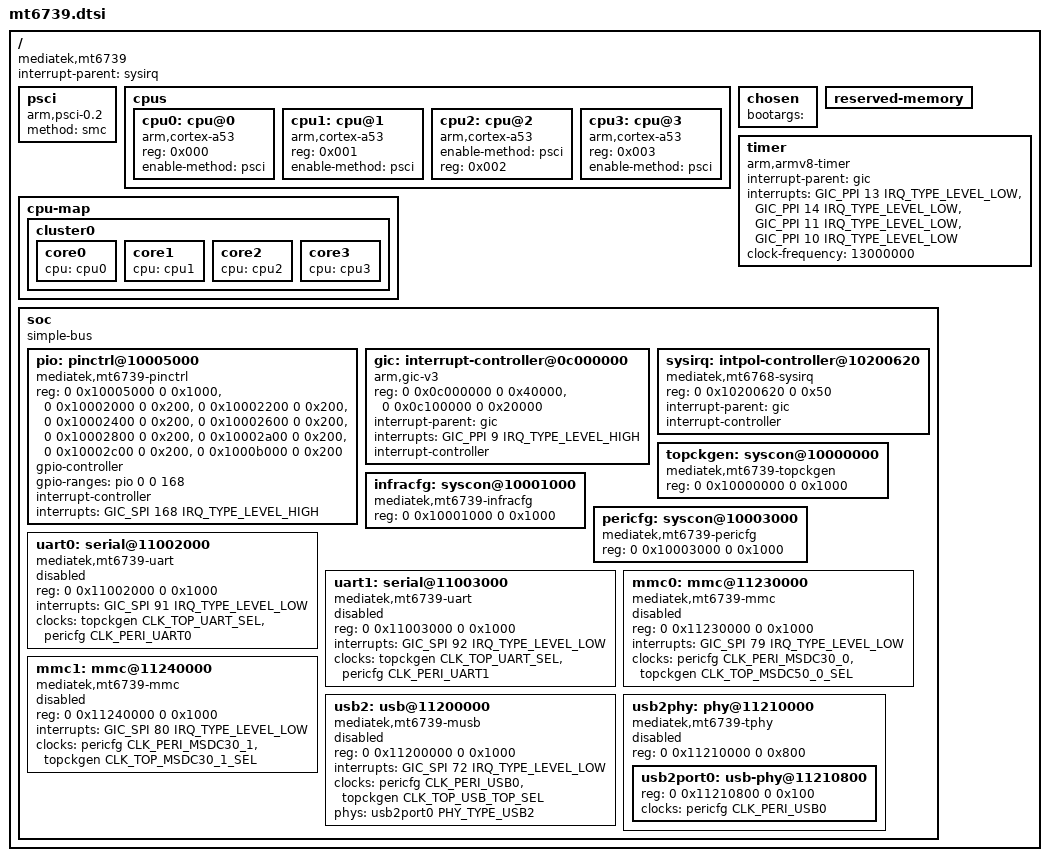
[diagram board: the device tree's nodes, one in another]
// SPDX-License-Identifier: GPL-2.0
/*
 * Copyright (c) 2024 Hoang Long
 */

#include <dt-bindings/clock/mt6739-clk.h>
#include <dt-bindings/interrupt-controller/irq.h>
#include <dt-bindings/interrupt-controller/arm-gic.h>
#include <dt-bindings/phy/phy.h>
#include <dt-bindings/pinctrl/mediatek,mt6739-pinfunc.h>

/ {
    compatible = "mediatek,mt6739";
    interrupt-parent = <&sysirq>;
    #address-cells = <2>;
    #size-cells = <2>;

    psci {
        compatible = "arm,psci-0.2";
        method = "smc";
    };

    cpus {
        #address-cells = <1>;
        #size-cells = <0>;

        cpu0: cpu@0 {
            device_type = "cpu";
            compatible = "arm,cortex-a53";
            reg = <0x000>;
            enable-method = "psci";
        };

        cpu1: cpu@1 {
            device_type = "cpu";
            compatible = "arm,cortex-a53";
            reg = <0x001>;
            enable-method = "psci";
        };

        cpu2: cpu@2 {
            device_type = "cpu";
            compatible = "arm,cortex-a53";
            enable-method = "psci";
            reg = <0x002>;
        };

        cpu3: cpu@3 {
            device_type = "cpu";
            compatible = "arm,cortex-a53";
            reg = <0x003>;
            enable-method = "psci";
        };
    };

    cpu-map {
        cluster0 {
            core0 {
                cpu = <&cpu0>;
            };
            core1 {
                cpu = <&cpu1>;
            };
            core2 {
                cpu = <&cpu2>;
            };
            core3 {
                cpu = <&cpu3>;
            };
        };
    };

	chosen {
		#address-cells = <2>;
		#size-cells = <2>;
		ranges;

		/*
		 * NOTE: /chosen/bootargs has to exist even if unused or
		 * bootloader will be unhappy
		 */
		bootargs = "";
	};

	reserved-memory {
		#address-cells = <2>;
		#size-cells = <2>;
		ranges;

		/* TODO: add useful non-mblock nodes from downstream! */
	};

    timer {
        compatible = "arm,armv8-timer";
        interrupt-parent = <&gic>;
        interrupts = <GIC_PPI 13 IRQ_TYPE_LEVEL_LOW>,
                     <GIC_PPI 14 IRQ_TYPE_LEVEL_LOW>,
                     <GIC_PPI 11 IRQ_TYPE_LEVEL_LOW>,
                     <GIC_PPI 10 IRQ_TYPE_LEVEL_LOW>;
        clock-frequency = <13000000>;
    };

    soc {
        #address-cells = <2>;
        #size-cells = <2>;
        compatible = "simple-bus";
        ranges;

        pio: pinctrl@10005000 {
            compatible = "mediatek,mt6739-pinctrl";
            reg = <0 0x10005000 0 0x1000>,
                  <0 0x10002000 0 0x200>,
                  <0 0x10002200 0 0x200>,
                  <0 0x10002400 0 0x200>,
                  <0 0x10002600 0 0x200>,
                  <0 0x10002800 0 0x200>,
                  <0 0x10002a00 0 0x200>,
                  <0 0x10002c00 0 0x200>,
                  <0 0x1000b000 0 0x200>;
            reg-names = "gpio", "iocfg_lt", "iocfg_lm", "iocfg_lb",
                  "iocfg_bl", "iocfg_bm", "iocfg_rb", "iocfg_rt",
                  "eint";
            gpio-controller;
            #gpio-cells = <2>;
            gpio-ranges = <&pio 0 0 168>;
            interrupt-controller;
            interrupts = <GIC_SPI 168 IRQ_TYPE_LEVEL_HIGH>;
            #interrupt-cells = <2>;
        };

        gic: interrupt-controller@0c000000 {
            compatible = "arm,gic-v3";
            reg = <0 0x0c000000 0 0x40000>, /* GICD */
                  <0 0x0c100000 0 0x20000>; /* GICR */
            #interrupt-cells = <3>;
            interrupt-parent = <&gic>;
            interrupts = <GIC_PPI 9 IRQ_TYPE_LEVEL_HIGH>;
            interrupt-controller;
        };

        sysirq: intpol-controller@10200620 {
			compatible = "mediatek,mt6768-sysirq", "mediatek,mt6577-sysirq";
            reg = <0 0x10200620 0 0x50>;	/* INTPOL */
            #interrupt-cells = <3>;
            interrupt-parent = <&gic>;
            interrupt-controller;
        };

        topckgen: syscon@10000000 {
            compatible = "mediatek,mt6739-topckgen", "syscon";
            reg = <0 0x10000000 0 0x1000>;
            #clock-cells = <1>;
        };

        infracfg: syscon@10001000 {
            compatible = "mediatek,mt6739-infracfg", "syscon";
            reg = <0 0x10001000 0 0x1000>;
            #clock-cells = <1>;
        };

        pericfg: syscon@10003000 {
            compatible = "mediatek,mt6739-pericfg", "syscon";
            reg = <0 0x10003000 0 0x1000>;
            #clock-cells = <1>;
        };

        uart0: serial@11002000 {
            compatible = "mediatek,mt6739-uart", "mediatek,mt6577-uart";
            reg = <0 0x11002000 0 0x1000>;
            interrupts = <GIC_SPI 91 IRQ_TYPE_LEVEL_LOW>;
            clocks = <&topckgen CLK_TOP_UART_SEL>, <&pericfg CLK_PERI_UART0>;
            clock-names = "baud", "bus";
            status = "disabled";
        };

        uart1: serial@11003000 {
            compatible = "mediatek,mt6739-uart", "mediatek,mt6577-uart";
            reg = <0 0x11003000 0 0x1000>;
            interrupts = <GIC_SPI 92 IRQ_TYPE_LEVEL_LOW>;
            clocks = <&topckgen CLK_TOP_UART_SEL>, <&pericfg CLK_PERI_UART1>;
            clock-names = "baud", "bus";
            status = "disabled";
        };

        mmc0: mmc@11230000 {
            compatible = "mediatek,mt6739-mmc", "mediatek,mt6765-mmc";
            reg = <0 0x11230000 0 0x1000>;
            interrupts = <GIC_SPI 79 IRQ_TYPE_LEVEL_LOW>;
            clocks = <&pericfg CLK_PERI_MSDC30_0>,
                     <&topckgen CLK_TOP_MSDC50_0_SEL>;
            clock-names = "source", "hclk";
            status = "disabled";
        };

        mmc1: mmc@11240000 {
            compatible = "mediatek,mt6739-mmc", "mediatek,mt6765-mmc";
            reg = <0 0x11240000 0 0x1000>;
            interrupts = <GIC_SPI 80 IRQ_TYPE_LEVEL_LOW>;
            clocks = <&pericfg CLK_PERI_MSDC30_1>,
                     <&topckgen CLK_TOP_MSDC30_1_SEL>;
            clock-names = "source", "hclk";
            status = "disabled";
        };

        usb2: usb@11200000 {
            compatible = "mediatek,mt6739-musb", "mediatek,mtk-musb";
            reg = <0 0x11200000 0 0x1000>;
            interrupts = <GIC_SPI 72 IRQ_TYPE_LEVEL_LOW>;
            interrupt-names = "mc";
            clocks = <&pericfg CLK_PERI_USB0>,
                     <&topckgen CLK_TOP_USB_TOP_SEL>;
            clock-names = "main", "mcu";
            phys = <&usb2port0 PHY_TYPE_USB2>;
            status = "disabled";
        };

        usb2phy: phy@11210000 {
            compatible = "mediatek,mt6739-tphy", "mediatek,generic-tphy-v1";
            reg = <0 0x11210000 0 0x800>;
            #address-cells = <2>;
            #size-cells = <2>;
            ranges;
            status = "disabled";

            usb2port0: usb-phy@11210800 {
                reg = <0 0x11210800 0 0x100>;
                clocks = <&pericfg CLK_PERI_USB0>;
                clock-names = "ref";
                #phy-cells = <1>;
            };
        };
    };
};
